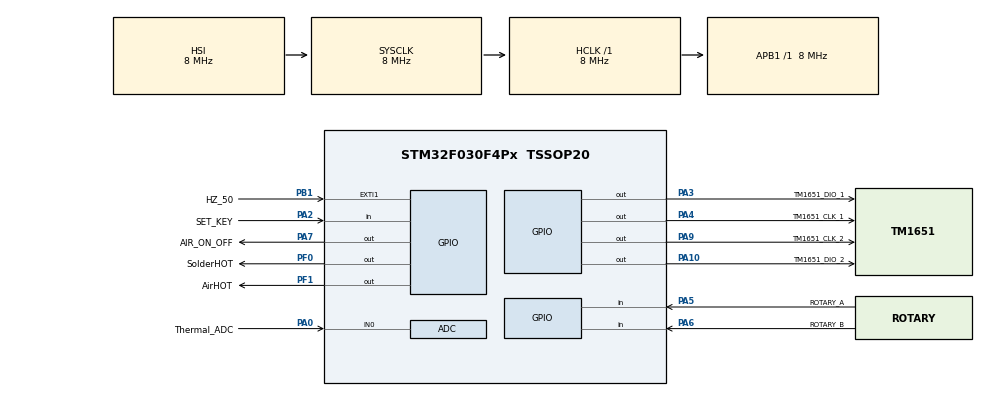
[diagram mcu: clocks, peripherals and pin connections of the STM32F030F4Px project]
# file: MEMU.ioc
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ADC.ContinuousConvMode=DISABLE
Mcu.Family=STM32F0
Mcu.Name=STM32F030F4Px
Mcu.Package=TSSOP20
NVIC.EXTI0_1_IRQn=true\:0\:0\:false\:false\:true
NVIC.TIM14_IRQn=true\:0\:0\:false\:false\:true
PA0.GPIO_Label=Thermal_ADC
PA0.Mode=IN0
PA0.Signal=ADC_IN0
PA10.GPIO_Label=TM1651_DIO_2
PA10.GPIO_PuPd=GPIO_PULLUP
PA10.Signal=GPIO_Output
PA2.GPIO_Label=SET_KEY
PA2.GPIO_PuPd=GPIO_PULLUP
PA2.Signal=GPIO_Input
PA3.GPIO_Label=TM1651_DIO_1
PA3.Signal=GPIO_Output
PA4.GPIO_Label=TM1651_CLK_1
PA4.Signal=GPIO_Output
PA5.GPIO_Label=ROTARY_A
PA5.GPIO_PuPd=GPIO_PULLUP
PA5.Signal=GPIO_Input
PA6.GPIO_Label=ROTARY_B
PA6.GPIO_PuPd=GPIO_PULLUP
PA6.Signal=GPIO_Input
PA7.GPIO_Label=AIR_ON_OFF
PA7.Signal=GPIO_Output
PA9.GPIO_Label=TM1651_CLK_2
PA9.GPIO_PuPd=GPIO_PULLUP
PA9.Signal=GPIO_Output
PB1.GPIO_Label=HZ_50
PB1.GPIO_PuPd=GPIO_PULLUP
PB1.Signal=GPXTI1
PF0-OSC_IN.GPIO_Label=SolderHOT
PF0-OSC_IN.Signal=GPIO_Output
PF1-OSC_OUT.GPIO_Label=AirHOT
PF1-OSC_OUT.Signal=GPIO_Output
ProjectManager.HeapSize=0x200
ProjectManager.StackSize=0x400
ProjectManager.TargetToolchain=MDK-ARM V5
RCC.AHBFreq_Value=8000000
RCC.APB1Freq_Value=8000000
RCC.APB1TimFreq_Value=8000000
RCC.HCLKFreq_Value=8000000
RCC.SYSCLKFreq_VALUE=8000000
RCC.Usart1ClockSelection=RCC_USART1CLKSOURCE_HSI
TIM14.Period=49
TIM14.Prescaler=7
VP_TIM14_VS_ClockSourceINT.Mode=Enable_Timer
board=MEMU

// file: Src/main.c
/**
  ******************************************************************************
  * File Name          : main.c
  * Description        : Main program body
  ******************************************************************************
  *
  * COPYRIGHT(c) 2016 STMicroelectronics
  *
  * Redistribution and use in source and binary forms, with or without modification,
  * are permitted provided that the following conditions are met:
  *   1. Redistributions of source code must retain the above copyright notice,
  *      this list of conditions and the following disclaimer.
  *   2. Redistributions in binary form must reproduce the above copyright notice,
  *      this list of conditions and the following disclaimer in the documentation
  *      and/or other materials provided with the distribution.
  *   3. Neither the name of STMicroelectronics nor the names of its contributors
  *      may be used to endorse or promote products derived from this software
  *      without specific prior written permission.
  *
  * THIS SOFTWARE IS PROVIDED BY THE COPYRIGHT HOLDERS AND CONTRIBUTORS "AS IS"
  * AND ANY EXPRESS OR IMPLIED WARRANTIES, INCLUDING, BUT NOT LIMITED TO, THE
  * IMPLIED WARRANTIES OF MERCHANTABILITY AND FITNESS FOR A PARTICULAR PURPOSE ARE
  * DISCLAIMED. IN NO EVENT SHALL THE COPYRIGHT HOLDER OR CONTRIBUTORS BE LIABLE
  * FOR ANY DIRECT, INDIRECT, INCIDENTAL, SPECIAL, EXEMPLARY, OR CONSEQUENTIAL
  * DAMAGES (INCLUDING, BUT NOT LIMITED TO, PROCUREMENT OF SUBSTITUTE GOODS OR
  * SERVICES; LOSS OF USE, DATA, OR PROFITS; OR BUSINESS INTERRUPTION) HOWEVER
  * CAUSED AND ON ANY THEORY OF LIABILITY, WHETHER IN CONTRACT, STRICT LIABILITY,
  * OR TORT (INCLUDING NEGLIGENCE OR OTHERWISE) ARISING IN ANY WAY OUT OF THE USE
  * OF THIS SOFTWARE, EVEN IF ADVISED OF THE POSSIBILITY OF SUCH DAMAGE.
  *
  ******************************************************************************
  */
#include "stm32f0xx_hal.h"
#include "adc.h"
#include "tim.h"
#include "gpio.h"

/* USER CODE BEGIN Includes */

#include "../tool/msg_task.h"
#include "../cantor/hotterctrl.h"

/* USER CODE END Includes */

/* USER CODE BEGIN PV */

/* Private variables ---------------------------------------------------------*/

/* USER CODE END PV */

void SystemClock_Config(void);
void Error_Handler(void);

/* USER CODE BEGIN PFP */
/* Private function prototypes -----------------------------------------------*/

/* USER CODE END PFP */

int main(void)
{

  /* MCU Configuration----------------------------------------------------------*/

  /* Reset of all peripherals, Initializes the Flash interface and the Systick. */
  HAL_Init();

  /* Configure the system clock */
  SystemClock_Config();

  /* Initialize all configured peripherals */
  MX_GPIO_Init();
  MX_ADC_Init();
  MX_TIM14_Init();

  /* USER CODE BEGIN 2 */

  HAL_ADCEx_Calibration_Start(&hadc);

  HAL_TIM_Base_Start(&htim14);
  HAL_ADC_PollForConversion(&hadc, 10);

  /* USER CODE END 2 */

  /* Infinite loop */
  /* USER CODE BEGIN WHILE */

	TaskSystickInit();
	TaskMainkInit();
//	solder1321_init();
	airK_init ();

  while (1)
  {

  /* USER CODE END WHILE */

  /* USER CODE BEGIN 3 */

	 TaskISR(&task_main);
	 TaskProcess(&task_main);

  }
  /* USER CODE END 3 */

}

/** System Clock Configuration
*/
void SystemClock_Config(void)
{

  RCC_OscInitTypeDef RCC_OscInitStruct;
  RCC_ClkInitTypeDef RCC_ClkInitStruct;

  RCC_OscInitStruct.OscillatorType = RCC_OSCILLATORTYPE_HSI|RCC_OSCILLATORTYPE_HSI14;
  RCC_OscInitStruct.HSIState = RCC_HSI_ON;
  RCC_OscInitStruct.HSI14State = RCC_HSI14_ON;
  RCC_OscInitStruct.HSICalibrationValue = 16;
  RCC_OscInitStruct.HSI14CalibrationValue = 16;
  RCC_OscInitStruct.PLL.PLLState = RCC_PLL_NONE;
  if (HAL_RCC_OscConfig(&RCC_OscInitStruct) != HAL_OK)
  {
    Error_Handler();
  }

  RCC_ClkInitStruct.ClockType = RCC_CLOCKTYPE_HCLK|RCC_CLOCKTYPE_SYSCLK
                              |RCC_CLOCKTYPE_PCLK1;
  RCC_ClkInitStruct.SYSCLKSource = RCC_SYSCLKSOURCE_HSI;
  RCC_ClkInitStruct.AHBCLKDivider = RCC_SYSCLK_DIV1;
  RCC_ClkInitStruct.APB1CLKDivider = RCC_HCLK_DIV1;
  if (HAL_RCC_ClockConfig(&RCC_ClkInitStruct, FLASH_LATENCY_0) != HAL_OK)
  {
    Error_Handler();
  }

  HAL_SYSTICK_Config(HAL_RCC_GetHCLKFreq()/1000);

  HAL_SYSTICK_CLKSourceConfig(SYSTICK_CLKSOURCE_HCLK);

  /* SysTick_IRQn interrupt configuration */
  HAL_NVIC_SetPriority(SysTick_IRQn, 0, 0);
}

void Error_Handler(void)
{
  while(1)
  {
  }
}

/************************ (C) COPYRIGHT STMicroelectronics *****END OF FILE****/
